CM_ "IMPORT _vw_mqbevo_common.dbc";

BO_ 252 ESC_51: 64 XXX
 SG_ CHECKSUM : 0|8@1+ (1,0) [0|255] "" XXX
 SG_ COUNTER : 8|4@1+ (1,0) [0|15] "" XXX
 SG_ NEW_SIGNAL_2 : 14|6@1+ (1,0) [0|3] "" XXX
 SG_ AEB_Breaking_01 : 24|8@1+ (1,0) [0|255] "" XXX
 SG_ AEB_Breaking_02 : 32|8@1+ (1,0) [0|255] "" XXX
 SG_ Accelerator_Higher_Speed : 40|1@0+ (1,0) [0|1] "" XXX
 SG_ Brake_Pressure : 42|9@1+ (0.195,0) [0|100] "Unit_Percent" XXX
 SG_ NEW_SIGNAL_1 : 52|8@1+ (1,0) [0|15] "" XXX
 SG_ HL_Radgeschw : 64|16@1+ (0.0075,0) [0|491.5125] "Unit_KilometerPerHour" XXX
 SG_ HR_Radgeschw : 80|16@1+ (0.0075,0) [0|491.5125] "Unit_KilometerPerHour" XXX
 SG_ VL_Radgeschw : 96|16@1+ (0.0075,0) [0|491.5125] "Unit_KilometerPerHour" XXX
 SG_ VR_Radgeschw : 112|16@1+ (0.0075,0) [0|491.5125] "Unit_KilometerPerHour" XXX
 SG_ NEW_SIGNAL_3 : 128|4@1+ (1,0) [0|15] "" XXX
 SG_ HL_Brake_Pressure : 152|8@1+ (1,0) [0|100] "" XXX
 SG_ HR_Brake_Pressure : 160|8@1+ (1,0) [0|100] "" XXX
 SG_ VL_Brake_Pressure : 168|8@1+ (1,0) [0|100] "" XXX
 SG_ VR_Brake_Pressure : 176|8@1+ (1,0) [0|100] "" XXX
 SG_ Steering_Wheel_CW : 184|8@1+ (1.67,0) [0|255] "" XXX
 SG_ Steering_Wheel_CCW : 192|8@1+ (1.67,0) [0|255] "" XXX
 SG_ ESC_v_Signal : 328|13@1+ (0.052,-107.016) [0|63] "" XXX
 SG_ NEW_SIGNAL_4 : 342|13@1+ (1,0) [0|3] "" XXX

BO_ 267 Motor_51: 48 XXX
 SG_ CHECKSUM : 0|8@1+ (1,0) [0|255] "" XXX
 SG_ COUNTER : 8|4@1+ (1,0) [0|15] "" XXX
 SG_ Accel_Pedal_Pressure : 12|9@1+ (0.4,0) [0|255] "" XXX
 SG_ Accel_Low_Pressed_Support : 21|1@1+ (1,0) [0|7] "" XXX
 SG_ TSK_Status : 88|3@1+ (1,0) [0|7] "" XXX
 SG_ TSK_Limiter_ausgewaehlt : 95|1@1+ (1,0) [0|3] "" XXX

BO_ 333 ACC_18: 32 XXX
 SG_ CHECKSUM : 0|8@1+ (1,0) [0|255] "" XXX
 SG_ COUNTER : 8|4@1+ (1,0) [0|15] "" XXX
 SG_ ACC_limitierte_Anfahrdyn : 12|1@1+ (1,0) [0|1] "" XXX
 SG_ ACC_nachtr_Stopp_Anf : 13|1@1+ (1,0) [0|1] "" XXX
 SG_ ACC_DynErhoehung : 14|1@1+ (1,0) [0|1] "" XXX
 SG_ ACC_Freilaufstrategie_TSK : 15|1@1+ (1,0) [0|1] "" XXX
 SG_ ACC_zul_Regelabw_unten : 16|6@1+ (0.024,0) [0|1.512] "Unit_MeterPerSeconSquar" XXX
 SG_ ACC_StartStopp_Info : 22|2@1+ (1,0) [0|3] "" XXX
 SG_ ACC_Sollbeschleunigung_02 : 24|11@1+ (0.005,-7.22) [-7.22|3.005] "Unit_MeterPerSeconSquar" XXX
 SG_ ACC_zul_Regelabw_oben : 35|5@1+ (0.0625,0) [0|1.9375] "Unit_MeterPerSeconSquar" XXX
 SG_ ACC_neg_Sollbeschl_Grad_02 : 40|8@1+ (0.05,0) [0|12.75] "Unit_MeterPerCubicSecon" XXX
 SG_ ACC_pos_Sollbeschl_Grad_02 : 48|8@1+ (0.05,0) [0|12.75] "Unit_MeterPerCubicSecon" XXX
 SG_ ACC_Anfahren : 56|1@1+ (1,0) [0|1] "" XXX
 SG_ ACC_Anhalten : 57|1@1+ (1,0) [0|1] "" XXX
 SG_ ACC_Typ : 58|2@1+ (1,0) [0|3] "" XXX
 SG_ ACC_Status_ACC : 60|3@1+ (1,0) [0|7] "" XXX
 SG_ ACC_Minimale_Bremsung : 63|1@1+ (1,0) [0|1] "" XXX
 SG_ ACC_Anhalteweg : 64|11@1+ (0.01,0) [0|2046] "" XXX
 SG_ ACC_Anforderung_HMS : 77|3@1+ (1,0) [0|7] "" XXX
 SG_ SET_ME_0XFE : 80|8@1+ (1,0) [0|255] "" XXX
 SG_ ACC_AKTIV_regelt : 90|1@0+ (1,0) [0|1] "" XXX
 SG_ SET_ME_0X1 : 92|1@0+ (1,0) [0|1] "" XXX
 SG_ SET_ME_0x2FE : 98|10@1+ (1,0) [0|63] "" XXX
 SG_ SET_ME_0X9 : 232|4@1+ (1,0) [0|15] "" XXX
 SG_ Speed : 236|12@1+ (0.1,0) [0|15] "" XXX
 SG_ Accel_Boost : 248|6@1+ (1,0) [0|3] "" XXX
 SG_ Reversing : 254|1@0+ (1,0) [0|1] "" XXX

BO_ 588 MEB_Side_Assist_01: 16 XXX
 SG_ Blind_Spot_Passenger : 12|7@1+ (1,0) [0|15] "" XXX
 SG_ Blind_Spot_Driver : 19|7@1+ (1,0) [0|15] "" XXX
 SG_ Blind_Spot_Info_Passenger : 26|1@0+ (1,0) [0|1] "" XXX
 SG_ Blind_Spot_Warn_Passenger : 27|1@0+ (1,0) [0|1] "" XXX
 SG_ Blind_Spot_Info_Driver : 29|1@0+ (1,0) [0|1] "" XXX
 SG_ Blind_Spot_Warn_Driver : 30|1@0+ (1,0) [0|1] "" XXX
 SG_ Lower_Speed_01 : 32|1@0+ (1,0) [0|1] "" XXX
 SG_ Higher_Speed_01 : 33|1@0+ (1,0) [0|1] "" XXX
 SG_ Higher_Speed_02 : 83|1@0+ (1,0) [0|1] "" XXX
 SG_ Lower_Speed_02 : 84|1@0+ (1,0) [0|1] "" XXX
 SG_ NEW_SIGNAL_1 : 98|1@0+ (1,0) [0|1] "" XXX
 SG_ NEW_SIGNAL_6 : 119|1@0+ (1,0) [0|1] "" XXX
 SG_ Motion_State : 171|2@0+ (1,0) [0|1] "" XXX

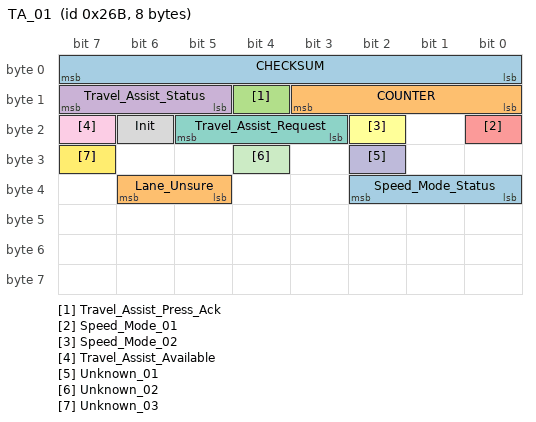
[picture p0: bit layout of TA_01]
BO_ 619 TA_01: 8 XXX
 SG_ CHECKSUM : 0|8@1+ (1,0) [0|255] "" XXX
 SG_ COUNTER : 8|4@1+ (1,0) [0|15] "" XXX
 SG_ Travel_Assist_Press_Ack : 12|1@1+ (1,0) [0|1] "" XXX
 SG_ Travel_Assist_Status : 13|3@1+ (1,0) [0|3] "" XXX
 SG_ Speed_Mode_01 : 16|1@0+ (1,0) [0|1] "" XXX
 SG_ Speed_Mode_02 : 18|1@0+ (1,0) [0|1] "" XXX
 SG_ Travel_Assist_Request : 19|3@1+ (1,0) [0|7] "" XXX
 SG_ Init : 22|1@0+ (1,0) [0|1] "" XXX
 SG_ Travel_Assist_Available : 23|1@1+ (1,0) [0|1] "" XXX
 SG_ Unknown_01 : 26|1@0+ (1,0) [0|1] "" XXX
 SG_ Unknown_02 : 28|1@0+ (1,0) [0|1] "" XXX
 SG_ Unknown_03 : 31|1@0+ (1,0) [0|1] "" XXX
 SG_ Speed_Mode_Status : 32|3@1+ (1,0) [0|7] "" XXX
 SG_ Lane_Unsure : 37|2@1+ (1,0) [0|3] "" XXX

VAL_ 267 TSK_Status 0 "init" 1 "disabled" 2 "enabled" 3 "regulating" 4 "accel_pedal_override" 5 "brake_only" 6 "temp_fault" 7 "perm_fault";
VAL_ 333 ACC_limitierte_Anfahrdyn 0 "keine_Limitierung" 1 "Limitierung_Anfahrdynamik_angefordert";
VAL_ 333 ACC_nachtr_Stopp_Anf 0 "nicht_angefordert" 1 "angefordert";
VAL_ 333 ACC_StartStopp_Info 0 "Motorlauf_langfristig_nicht_notwendig_Stoppfreigabe" 1 "Motoranlauf_nicht_zwingend_notwendig_Stoppverbot_keine_Startanforderung" 2 "Motoranlauf_zwingend_notwendig_Startanforderung" 3 "Systemfehler";
VAL_ 333 ACC_Sollbeschleunigung_02 2046 "Neutralwert" 2047 "Fehler";
VAL_ 333 ACC_Anfahren 0 "keine_Anforderung_Anfahren" 1 "Anforderung_Anfahren";
VAL_ 333 ACC_Anhalten 0 "kein_Anhalten_gewuenscht" 1 "Anhalten_gewuenscht";
VAL_ 333 ACC_Typ 0 "Basis_ACC" 1 "ACC_mit_FollowToStop" 2 "ACC_mit_StopAndGo" 3 "ACC_nicht_codiert";
VAL_ 333 ACC_Status_ACC 0 "ACC_OFF_Hauptschalter_aus" 1 "ACC_INIT" 2 "ACC_STANDBY" 3 "ACC_AKTIV_regelt" 4 "ACC_OVERRIDE" 5 "ACC_Abschaltreaktion" 6 "reversibler_Fehler_im_ACC_System" 7 "irreversibler_Fehler_im_ACC_System";
VAL_ 333 ACC_Minimale_Bremsung 0 "Anforderung_Minimale_Bremsung_nicht_aktiv" 1 "Anforderung_Minimale_Bremsung_aktiv";
VAL_ 333 ACC_Anhalteweg 2046 "Neutralwert" 2047 "Fehler";
VAL_ 333 ACC_Anforderung_HMS 0 "keine_Anforderung" 1 "halten" 2 "parken" 3 "halten_Standby" 4 "anfahren" 5 "Loesen_ueber_Rampe";
VAL_ 333 Accel_Boost 3 "Driving" 0 "Stop" 2 "Driving" 1 "Driving";
VAL_ 588 Motion_State 1 "Forwards" 2 "Reversing" 3 "Stopped";
VAL_ 619 Travel_Assist_Status 4 "enabled" 0 "disabled" 2 "ready" 3 "pre_ready";
VAL_ 619 Travel_Assist_Request 4 "enable" 3 "disable" 0 "no_request" 1 "error";
VAL_ 619 Travel_Assist_Available 0 "not_available" 1 "available";
